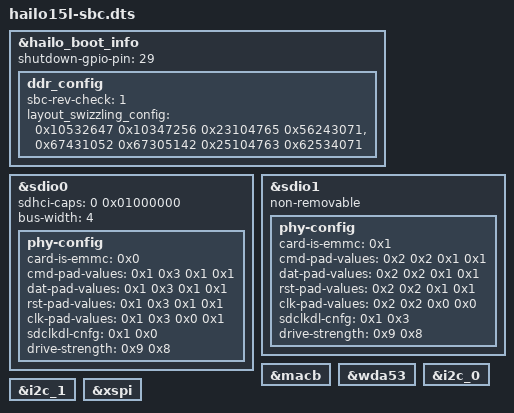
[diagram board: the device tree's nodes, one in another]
// SPDX-License-Identifier: GPL-2.0
/*
 * dts file for Hailo15l SBC SoC
 *
 * Copyright (c) 2019-2024 Hailo Technologies Ltd. All rights reserved.
 */

#include "hailo15l-base.dtsi"
#include "hailo15_ddr_configuration.dtsi"
#include "hailo15l_ddr_MT53E512M32D1-046_regconfig_2GB_lpddr4x.dtsi"

&hailo_boot_info {
	ddr_config {
        sbc-rev-check = <1>;
        layout_swizzling_config = <0x10532647 0x10347256 0x23104765 0x56243071>, // Hailo15l-SBC Rev1
                                  <0x67431052 0x67305142 0x25104763 0x62534071>; // Hailo15l-SBC Rev2
    };
};

&sdio0 {
    status = "okay";
    sdhci-caps = <0 0x01000000>; // Force VOLT33 capability
    bus-width = <4>;

    phy-config {
            card-is-emmc = <0x0>;
            cmd-pad-values = <0x1 0x3 0x1 0x1>; // txslew_ctrl_n, txslew_ctrl_p, weakpull_enable, rxsel
            dat-pad-values = <0x1 0x3 0x1 0x1>; // txslew_ctrl_n, txslew_ctrl_p, weakpull_enable, rxsel
            rst-pad-values = <0x1 0x3 0x1 0x1>; // txslew_ctrl_n, txslew_ctrl_p, weakpull_enable, rxsel
            clk-pad-values = <0x1 0x3 0x0 0x1>; // txslew_ctrl_n, txslew_ctrl_p, weakpull_enable, rxsel
            sdclkdl-cnfg = <0x1 0x0>; //extdly_en, cckdl_dc
            drive-strength = <0x9 0x8>; //pad_sp, pad_sn
            u-boot,dm-spl;
    };
};

&sdio1 {
    status = "okay";
    non-removable;
    phy-config {
            card-is-emmc = <0x1>;
            cmd-pad-values = <0x2 0x2 0x1 0x1>; // txslew_ctrl_n, txslew_ctrl_p, weakpull_enable, rxsel
            dat-pad-values = <0x2 0x2 0x1 0x1>; // txslew_ctrl_n, txslew_ctrl_p, weakpull_enable, rxsel
            rst-pad-values = <0x2 0x2 0x1 0x1>; // txslew_ctrl_n, txslew_ctrl_p, weakpull_enable, rxsel
            clk-pad-values = <0x2 0x2 0x0 0x0>; // txslew_ctrl_n, txslew_ctrl_p, weakpull_enable, rxsel
            sdclkdl-cnfg = <0x1 0x3>; //extdly_en, cckdl_dc
            drive-strength = <0x9 0x8>; //pad_sp, pad_sn 
            u-boot,dm-spl;   
    };
};

&macb {
    status = "okay";
};

&wda53 {
    status = "okay";
};

&hailo_boot_info {
    shutdown-gpio-pin = <29>;
};

&i2c_0 {
    status = "okay";
};

&i2c_1 {
    status = "okay";
};

&xspi {
    status = "okay";
};
